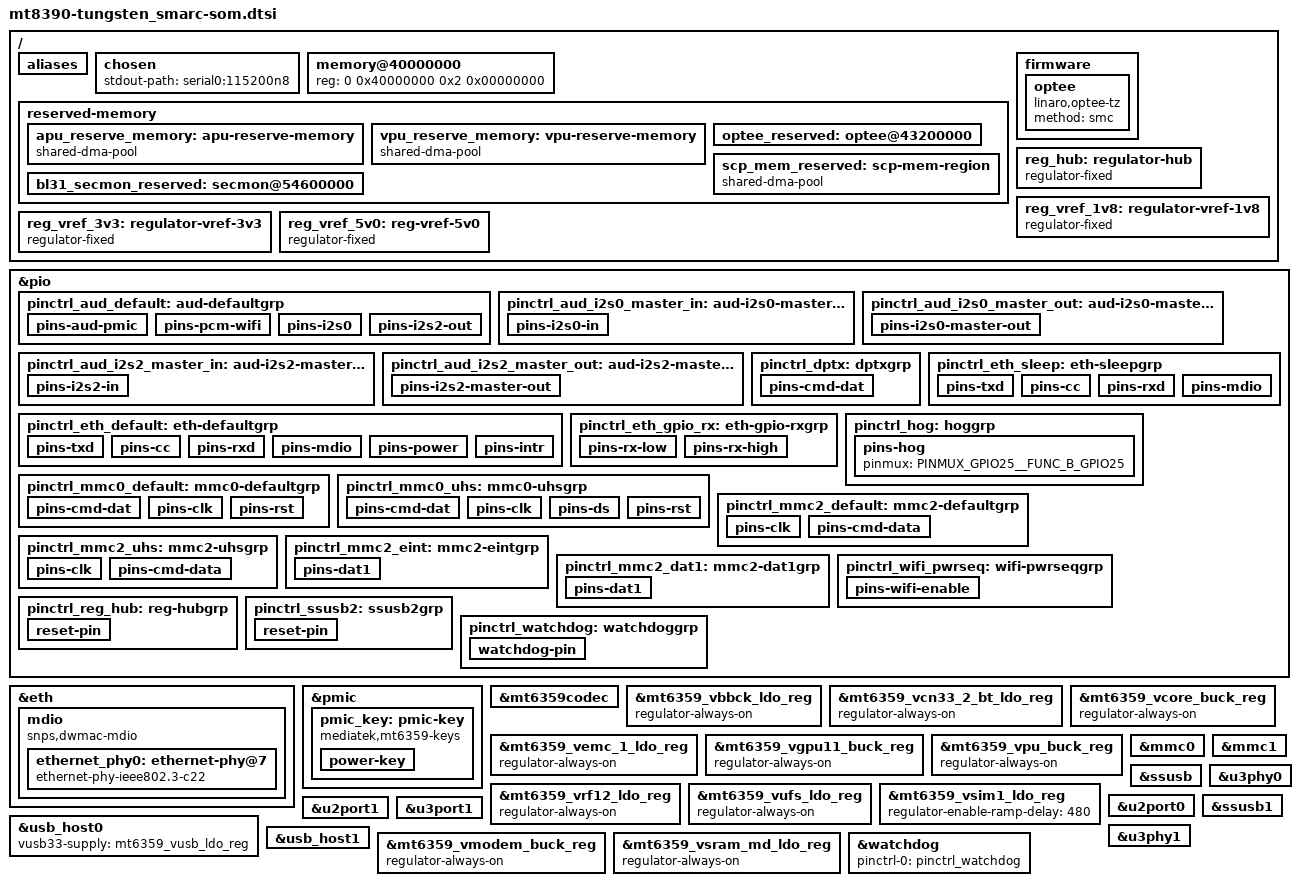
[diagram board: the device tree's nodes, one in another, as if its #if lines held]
// SPDX-License-Identifier: (GPL-2.0 OR MIT)
/*
 * Copyright 2023 Boundary Devices
 */
/dts-v1/;
#include "mt8188.dtsi"
#include "mt6359.dtsi"
#include <dt-bindings/gpio/gpio.h>
#include <dt-bindings/input/input.h>
#include <dt-bindings/interrupt-controller/irq.h>
#include <dt-bindings/net/microchip-lan78xx.h>
#include <dt-bindings/pinctrl/mediatek,mt8188-pinfunc.h>
#include <dt-bindings/usb/pd.h>
#ifdef CONFIG_DEFCONFIG
#define UBOOT
#endif
#ifdef UBOOT
#define GPIO	gpio
#else
#define GPIO	pio
#endif

#define USE_I2SIN_WITH_I2SO1

&pio {
	pinctrl_aud_default: aud-defaultgrp {
		pins-aud-pmic {
			pinmux = <
				PINMUX_GPIO101__FUNC_O_AUD_CLK_MOSI
				PINMUX_GPIO102__FUNC_O_AUD_SYNC_MOSI
				PINMUX_GPIO103__FUNC_O_AUD_DAT_MOSI0
				PINMUX_GPIO104__FUNC_O_AUD_DAT_MOSI1
				PINMUX_GPIO105__FUNC_I0_AUD_DAT_MISO0
				PINMUX_GPIO106__FUNC_I0_AUD_DAT_MISO1
			>;
		};

		pins-pcm-wifi {
			pinmux = <
				PINMUX_GPIO121__FUNC_B0_PCM_CLK		/* PCM_CLK */
				PINMUX_GPIO122__FUNC_B0_PCM_SYNC	/* PCM_SYNC */
				PINMUX_GPIO123__FUNC_O_PCM_DO		/* PCM_DO */
				PINMUX_GPIO124__FUNC_I0_PCM_DI		/* PCM_DI */
			>;
		};

		//i2s0 I2SO1 is master
		pins-i2s0 {
			pinmux = <
				PINMUX_GPIO119__FUNC_O_I2SO1_MCK	/* I2SO2_D2 */
				PINMUX_GPIO112__FUNC_O_I2SO1_WS		/* I2SIN_D2 */
				PINMUX_GPIO120__FUNC_O_I2SO1_BCK	/* I2SO2_D3 */
				PINMUX_GPIO113__FUNC_O_I2SO1_D0		/* I2SIN_D3 */

				PINMUX_GPIO107__FUNC_B_GPIO107		/* I2SIN_MCK */
				PINMUX_GPIO108__FUNC_B_GPIO108		/* I2SIN_BCK */
				PINMUX_GPIO109__FUNC_B_GPIO109		/* I2SIN_WS */
#ifdef USE_I2SIN_WITH_I2SO1
				PINMUX_GPIO110__FUNC_I0_I2SIN_D0	/* I2SIN_D0 */
#else
				PINMUX_GPIO110__FUNC_I0_SPLIN_D0	/* I2SIN_D0 */
#endif
			>;
		};

		//i2s2
		pins-i2s2-out {
			pinmux = <
				PINMUX_GPIO116__FUNC_B0_I2SO2_WS	/* I2SO2_WS */
				PINMUX_GPIO115__FUNC_B0_I2SO2_BCK	/* I2SO2_BCK */
				PINMUX_GPIO117__FUNC_O_I2SO2_D0		/* I2SO2_D0 */
			>;
		};
	};

	pinctrl_aud_i2s0_master_in: aud-i2s0-master-ingrp {
		pins-i2s0-in {
			pinmux = <
				PINMUX_GPIO107__FUNC_I0_SPLIN_MCK	/* I2SIN_MCK */
				PINMUX_GPIO119__FUNC_B_GPIO119		/* I2SO2_D2 */
				PINMUX_GPIO108__FUNC_I0_SPLIN_LRCK	/* I2SIN_BCK */
				PINMUX_GPIO112__FUNC_B_GPIO112		/* I2SIN_D2 */
				PINMUX_GPIO109__FUNC_I0_SPLIN_BCK	/* I2SIN_WS */
				PINMUX_GPIO120__FUNC_B_GPIO120		/* I2SO2_D3 */
				PINMUX_GPIO110__FUNC_I0_SPLIN_D0	/* I2SIN_D0 */
			>;
		};
	};

	pinctrl_aud_i2s0_master_out: aud-i2s0-master-outgrp {
		pins-i2s0-master-out {
			pinmux = <
				PINMUX_GPIO107__FUNC_B_GPIO107		/* I2SIN_MCK */
				PINMUX_GPIO119__FUNC_O_I2SO1_MCK	/* I2SO2_D2 */
				PINMUX_GPIO108__FUNC_B_GPIO108		/* I2SIN_BCK */
				PINMUX_GPIO112__FUNC_O_I2SO1_WS		/* I2SIN_D2 */
				PINMUX_GPIO109__FUNC_B_GPIO109		/* I2SIN_WS */
				PINMUX_GPIO120__FUNC_O_I2SO1_BCK	/* I2SO2_D3 */
				PINMUX_GPIO113__FUNC_O_I2SO1_D0		/* I2SIN_D3 */
			>;
		};
	};

	pinctrl_aud_i2s2_master_in: aud-i2s2-master-ingrp {
		pins-i2s2-in {
			pinmux = <
				PINMUX_GPIO116__FUNC_B0_I2SIN_WS	/* I2SO2_WS */
				PINMUX_GPIO115__FUNC_B0_I2SIN_BCK	/* I2SO2_BCK */
				PINMUX_GPIO118__FUNC_I0_I2SIN_D1	/* I2SO2_D1 */
			>;
		};
	};

	pinctrl_aud_i2s2_master_out: aud-i2s2-master-outgrp {
		pins-i2s2-master-out {
			pinmux = <
				PINMUX_GPIO116__FUNC_B0_I2SO2_WS	/* I2SO2_WS */
				PINMUX_GPIO115__FUNC_B0_I2SO2_BCK	/* I2SO2_BCK */
				PINMUX_GPIO117__FUNC_O_I2SO2_D0		/* I2SO2_D0 */
			>;
		};
	};

	pinctrl_dptx: dptxgrp {
		pins-cmd-dat {
			pinmux = <PINMUX_GPIO46__FUNC_I0_DP_TX_HPD>;
			bias-pull-up;
		};
	};

	pinctrl_eth_default: eth-defaultgrp {
		pins-txd {
			pinmux = <PINMUX_GPIO131__FUNC_O_GBE_TXD3>,
				 <PINMUX_GPIO132__FUNC_O_GBE_TXD2>,
				 <PINMUX_GPIO133__FUNC_O_GBE_TXD1>,
				 <PINMUX_GPIO134__FUNC_O_GBE_TXD0>;
			drive-strength = <MTK_DRIVE_8mA>;
		};
		pins-cc {
			pinmux = <PINMUX_GPIO139__FUNC_B0_GBE_TXC>,
				 <PINMUX_GPIO142__FUNC_O_GBE_TXEN>,
				 <PINMUX_GPIO141__FUNC_I0_GBE_RXDV>,
				 <PINMUX_GPIO140__FUNC_I0_GBE_RXC>;
			drive-strength = <MTK_DRIVE_8mA>;
		};
		pins-rxd {
			pinmux = <PINMUX_GPIO135__FUNC_I0_GBE_RXD3>,
				 <PINMUX_GPIO136__FUNC_I0_GBE_RXD2>,
				 <PINMUX_GPIO137__FUNC_I0_GBE_RXD1>,
				 <PINMUX_GPIO138__FUNC_I0_GBE_RXD0>;
			drive-strength = <MTK_DRIVE_8mA>;
		};
		pins-mdio {
			pinmux = <PINMUX_GPIO143__FUNC_O_GBE_MDC>,
				 <PINMUX_GPIO144__FUNC_B1_GBE_MDIO>;
			drive-strength = <MTK_DRIVE_2mA>;
			input-enable;
		};
#ifdef UBOOT
		pins-power {
#define GP_EQOS_RESET	<&GPIO 27 GPIO_ACTIVE_LOW>
			pinmux = <PINMUX_GPIO27__FUNC_B_GPIO27>;
			output-high;
		};
#endif
		pins-intr {
#define GPIRQ_EQOS_PHY	<&pio 148 IRQ_TYPE_LEVEL_LOW>
			pinmux = <PINMUX_GPIO148__FUNC_B_GPIO148>;
			input-enable;
		};
	};

	pinctrl_eth_sleep: eth-sleepgrp {
		pins-txd {
			pinmux = <PINMUX_GPIO131__FUNC_B_GPIO131>,
				 <PINMUX_GPIO132__FUNC_B_GPIO132>,
				 <PINMUX_GPIO133__FUNC_B_GPIO133>,
				 <PINMUX_GPIO134__FUNC_B_GPIO134>;
		};
		pins-cc {
			pinmux = <PINMUX_GPIO139__FUNC_B_GPIO139>,
				 <PINMUX_GPIO142__FUNC_B_GPIO142>,
				 <PINMUX_GPIO141__FUNC_B_GPIO141>,
				 <PINMUX_GPIO140__FUNC_B_GPIO140>;
		};
		pins-rxd {
			pinmux = <PINMUX_GPIO135__FUNC_B_GPIO135>,
				 <PINMUX_GPIO136__FUNC_B_GPIO136>,
				 <PINMUX_GPIO137__FUNC_B_GPIO137>,
				 <PINMUX_GPIO138__FUNC_B_GPIO138>;
		};
		pins-mdio {
			pinmux = <PINMUX_GPIO143__FUNC_B_GPIO143>,
				 <PINMUX_GPIO144__FUNC_B_GPIO144>;
			input-disable;
			bias-disable;
		};
	};

	pinctrl_eth_gpio_rx: eth-gpio-rxgrp {
		pins-rx-low {
			pinmux =
#define GP_PHY_RX_CTL		<&GPIO 141 GPIO_ACTIVE_HIGH>
				<PINMUX_GPIO141__FUNC_B_GPIO141>;
			output-low;
		};
		pins-rx-high {
			pinmux =
#define GP_PHY_RD0		<&GPIO 135 GPIO_ACTIVE_HIGH>
				<PINMUX_GPIO135__FUNC_B_GPIO135>,
#define GP_PHY_RD1		<&GPIO 136 GPIO_ACTIVE_HIGH>
				<PINMUX_GPIO136__FUNC_B_GPIO136>,
#define GP_PHY_RD2		<&GPIO 137 GPIO_ACTIVE_HIGH>
				<PINMUX_GPIO137__FUNC_B_GPIO137>,
#define GP_PHY_RD3		<&GPIO 138 GPIO_ACTIVE_HIGH>
				<PINMUX_GPIO138__FUNC_B_GPIO138>,
#define GP_PHY_RXC		<&GPIO 140 GPIO_ACTIVE_HIGH>
				<PINMUX_GPIO140__FUNC_B_GPIO140>;
			output-high;
		};
	};


	pinctrl_hog: hoggrp {
		pins-hog {
#define GP_DP0_HPD(a)	<&GPIO 25 a>	/* LCM_RST */
			pinmux = <PINMUX_GPIO25__FUNC_B_GPIO25>;
		};
	};

	pinctrl_mmc0_default: mmc0-defaultgrp {
		pins-cmd-dat {
			pinmux = <PINMUX_GPIO161__FUNC_B1_MSDC0_DAT0>,
				 <PINMUX_GPIO160__FUNC_B1_MSDC0_DAT1>,
				 <PINMUX_GPIO159__FUNC_B1_MSDC0_DAT2>,
				 <PINMUX_GPIO158__FUNC_B1_MSDC0_DAT3>,
				 <PINMUX_GPIO154__FUNC_B1_MSDC0_DAT4>,
				 <PINMUX_GPIO153__FUNC_B1_MSDC0_DAT5>,
				 <PINMUX_GPIO152__FUNC_B1_MSDC0_DAT6>,
				 <PINMUX_GPIO151__FUNC_B1_MSDC0_DAT7>,
				 <PINMUX_GPIO156__FUNC_B1_MSDC0_CMD>;
			input-enable;
			drive-strength = <MTK_DRIVE_6mA>;
			bias-pull-up = <MTK_PUPD_SET_R1R0_01>;
		};

		pins-clk {
			pinmux = <PINMUX_GPIO157__FUNC_B1_MSDC0_CLK>;
			drive-strength = <MTK_DRIVE_6mA>;
			bias-pull-down = <MTK_PUPD_SET_R1R0_10>;
		};

		pins-rst {
			pinmux = <PINMUX_GPIO155__FUNC_O_MSDC0_RSTB>;
			drive-strength = <MTK_DRIVE_6mA>;
			bias-pull-up = <MTK_PUPD_SET_R1R0_01>;
		};
	};

	pinctrl_mmc0_uhs: mmc0-uhsgrp{
		pins-cmd-dat {
			pinmux = <PINMUX_GPIO161__FUNC_B1_MSDC0_DAT0>,
				 <PINMUX_GPIO160__FUNC_B1_MSDC0_DAT1>,
				 <PINMUX_GPIO159__FUNC_B1_MSDC0_DAT2>,
				 <PINMUX_GPIO158__FUNC_B1_MSDC0_DAT3>,
				 <PINMUX_GPIO154__FUNC_B1_MSDC0_DAT4>,
				 <PINMUX_GPIO153__FUNC_B1_MSDC0_DAT5>,
				 <PINMUX_GPIO152__FUNC_B1_MSDC0_DAT6>,
				 <PINMUX_GPIO151__FUNC_B1_MSDC0_DAT7>,
				 <PINMUX_GPIO156__FUNC_B1_MSDC0_CMD>;
			input-enable;
			drive-strength = <MTK_DRIVE_8mA>;
			bias-pull-up = <MTK_PUPD_SET_R1R0_01>;
		};

		pins-clk {
			pinmux = <PINMUX_GPIO157__FUNC_B1_MSDC0_CLK>;
			drive-strength = <MTK_DRIVE_8mA>;
			bias-pull-down = <MTK_PUPD_SET_R1R0_10>;
		};

		pins-ds {
			pinmux = <PINMUX_GPIO162__FUNC_B0_MSDC0_DSL>;
			drive-strength = <MTK_DRIVE_8mA>;
			bias-pull-down = <MTK_PUPD_SET_R1R0_10>;
		};

		pins-rst {
			pinmux = <PINMUX_GPIO155__FUNC_O_MSDC0_RSTB>;
			drive-strength = <MTK_DRIVE_8mA>;
			bias-pull-up = <MTK_PUPD_SET_R1R0_01>;
		};
	};

	pinctrl_mmc2_default: mmc2-defaultgrp {
		pins-clk {
			pinmux = <PINMUX_GPIO170__FUNC_B1_MSDC2_CLK>;
			drive-strength = <MTK_DRIVE_4mA>;
			bias-pull-down = <MTK_PUPD_SET_R1R0_10>;
		};

		pins-cmd-data {
			pinmux = <PINMUX_GPIO169__FUNC_B1_MSDC2_CMD>,
				 <PINMUX_GPIO171__FUNC_B1_MSDC2_DAT0>,
				 <PINMUX_GPIO172__FUNC_B1_MSDC2_DAT1>,
				 <PINMUX_GPIO173__FUNC_B1_MSDC2_DAT2>,
				 <PINMUX_GPIO174__FUNC_B1_MSDC2_DAT3>;
			input-enable;
			drive-strength = <MTK_DRIVE_6mA>;
			bias-pull-up = <MTK_PUPD_SET_R1R0_01>;
		};
	};

	pinctrl_mmc2_uhs: mmc2-uhsgrp {
		pins-clk {
			pinmux = <PINMUX_GPIO170__FUNC_B1_MSDC2_CLK>;
			drive-strength = <MTK_DRIVE_4mA>;
			bias-pull-down = <MTK_PUPD_SET_R1R0_10>;
		};

		pins-cmd-data {
			pinmux = <PINMUX_GPIO169__FUNC_B1_MSDC2_CMD>,
				 <PINMUX_GPIO171__FUNC_B1_MSDC2_DAT0>,
				 <PINMUX_GPIO172__FUNC_B1_MSDC2_DAT1>,
				 <PINMUX_GPIO173__FUNC_B1_MSDC2_DAT2>,
				 <PINMUX_GPIO174__FUNC_B1_MSDC2_DAT3>;
			input-enable;
			drive-strength = <MTK_DRIVE_6mA>;
			bias-pull-up = <MTK_PUPD_SET_R1R0_01>;
		};
	};

	pinctrl_mmc2_eint: mmc2-eintgrp {
		pins-dat1 {
#define GP_MMC2_DATA1	<&GPIO 172 GPIO_ACTIVE_HIGH>
			pinmux = <PINMUX_GPIO172__FUNC_B_GPIO172>;
			input-enable;
			bias-pull-up = <MTK_PUPD_SET_R1R0_01>;
		};
	};

	pinctrl_mmc2_dat1: mmc2-dat1grp {
		pins-dat1 {
			pinmux = <PINMUX_GPIO172__FUNC_B1_MSDC2_DAT1>;
			input-enable;
			drive-strength = <MTK_DRIVE_6mA>;
			bias-pull-up = <MTK_PUPD_SET_R1R0_01>;
		};
	};

	pinctrl_wifi_pwrseq: wifi-pwrseqgrp {
		pins-wifi-enable {
#define GP_WIFI_RESET	<&GPIO 89 GPIO_ACTIVE_LOW>
			pinmux = <PINMUX_GPIO89__FUNC_B_GPIO89>;	/* USB2_IDDIG */
			output-low;
		};
	};

	pinctrl_reg_hub: reg-hubgrp {
		reset-pin {
#define GP_HUB_ENABLE	<&GPIO 147 GPIO_ACTIVE_HIGH>			/* HUB_RESET */
			pinmux = <PINMUX_GPIO147__FUNC_B_GPIO147>;	/* DPI_HSYNC */
			output-low;
		};
	};

	pinctrl_ssusb2: ssusb2grp {
		reset-pin {
#define GP_SSUSB2_RESET	<&GPIO 80 GPIO_ACTIVE_LOW>
			pinmux = <PINMUX_GPIO80__FUNC_B_GPIO80>;	/* SPIM2_CLK */
			output-low;
		};
	};

	pinctrl_watchdog: watchdoggrp {
		watchdog-pin {
			pinmux = <PINMUX_GPIO100__FUNC_O_WATCHDOG>;	/* PMIC_WATCHDOG */
			bias-pull-up;
		};
	};
};

/ {
	aliases {
		serial0 = &uart0;
		ethernet0 = &eth;
		rtc1 = &mt6359rtc;
	};

	chosen {
		stdout-path = "serial0:115200n8";
	};

	memory@40000000 {
		device_type = "memory";
		reg = <0 0x40000000 0x2 0x00000000>;
	};

	reserved-memory {
		#address-cells = <2>;
		#size-cells = <2>;
		ranges;

		apu_reserve_memory: apu-reserve-memory{
			compatible = "shared-dma-pool";
			size = <0 0x1400000>; //20 MB
			alignment = <0 0x10000>;
			reg = <0 0x55000000 0 0x1400000>;
		};

		vpu_reserve_memory: vpu-reserve-memory {
			compatible = "shared-dma-pool";
			size = <0 0x1400000>; //20 MB
			alignment = <0 0x10000>;
			reg = <0 0x57000000 0 0x1400000>;
		};

		/* 12 MiB reserved for OP-TEE (BL32)
		 * +-----------------------+ 0x43e0_0000
		 * |      SHMEM 2MiB       |
		 * +-----------------------+ 0x43c0_0000
		 * |        | TA_RAM  8MiB |
		 * + TZDRAM +--------------+ 0x4340_0000
		 * |        | TEE_RAM 2MiB |
		 * +-----------------------+ 0x4320_0000
		 */
		optee_reserved: optee@43200000 {
			no-map;
			reg = <0 0x43200000 0 0x00c00000>;
		};

		scp_mem_reserved: scp-mem-region {
			compatible = "shared-dma-pool";
			reg = <0 0x50000000 0 0x2900000>;
			no-map;
		};

		/* 2 MiB reserved for ARM Trusted Firmware (BL31) */
		bl31_secmon_reserved: secmon@54600000 {
			no-map;
			reg = <0 0x54600000 0x0 0x200000>;
		};
	};

	firmware {
		optee {
			compatible = "linaro,optee-tz";
			method = "smc";
		};
	};

	reg_hub: regulator-hub {
		compatible = "regulator-fixed";
		enable-active-high;
		gpio = GP_HUB_ENABLE;
		pinctrl-0 = <&pinctrl_reg_hub>;
		pinctrl-names = "default";
		regulator-name = "hub_reset";
		regulator-min-microvolt = <1800000>;
		regulator-max-microvolt = <1800000>;
	};

	reg_vref_1v8: regulator-vref-1v8 {
		compatible = "regulator-fixed";
		regulator-name = "vref-1v8";
		regulator-min-microvolt = <1800000>;
		regulator-max-microvolt = <1800000>;
		regulator-always-on;
	};

	reg_vref_3v3: regulator-vref-3v3 {
		compatible = "regulator-fixed";
		regulator-name = "vref-3v3";
		regulator-min-microvolt = <3300000>;
		regulator-max-microvolt = <3300000>;
		regulator-always-on;
	};

	reg_vref_5v0: reg-vref-5v0 {
		compatible = "regulator-fixed";
		regulator-name = "vref-5v0";
		regulator-min-microvolt = <5000000>;
		regulator-max-microvolt = <5000000>;
		regulator-always-on;
	};
};

#ifndef UBOOT
&afe {
	#sound-dai-cells = <0>;
	mediatek,etdm-in1-multi-pin-mode;	/* I2S */
	mediatek,etdm-in2-multi-pin-mode;	/* I2S */
	mediatek,etdm-out1-multi-pin-mode;	/* I2S */
	mediatek,etdm-out2-multi-pin-mode;	/* I2S */
#ifdef USE_I2SIN_WITH_I2SO1
	mediatek,etdm-in1-cowork-source = <3>;	/* clocks from etdm2_out */
	mediatek,etdm-in2-cowork-source = <2>;	/* clocks from etdm1_out */
#else
	mediatek,etdm-in1-cowork-source = <2>;	/* clocks from etdm1_out */
	mediatek,etdm-in2-cowork-source = <3>;	/* clocks from etdm2_out */
#endif
	status = "okay";
};
#endif

&eth {
	avddh-supply = <&mt6359_vpa_buck_reg>;
	mediatek,mac-wol;
	phy-mode ="rgmii-rxid";
	phy-handle = <&ethernet_phy0>;
	pinctrl-names = "default", "sleep", "gpio-rx";
	pinctrl-0 = <&pinctrl_eth_default>;
	pinctrl-1 = <&pinctrl_eth_sleep>;
	pinctrl-2 = <&pinctrl_eth_gpio_rx>;
	status = "okay";

	mdio {
		compatible = "snps,dwmac-mdio";
		#address-cells = <1>;
		#size-cells = <0>;

		ethernet_phy0: ethernet-phy@7 {
			compatible = "ethernet-phy-ieee802.3-c22";
			eee-broken-1000t;
			interrupts-extended = GPIRQ_EQOS_PHY;
			reg = <0x7>;
#ifdef GP_EQOS_RESET
			reset-gpios = GP_EQOS_RESET;
#endif
		};
	};
};

#ifndef UBOOT
&dpi1 {
	status = "okay";
};

&dp_intf1 {
	status = "disabled";
	ports {
		port {
			dp_intf1_out: endpoint {
				remote-endpoint = <&dptx_in>;
			};
		};
	};
};

&dp_tx {
	pinctrl-names = "default";
	pinctrl-0 = <&pinctrl_dptx>;
	status = "disabled";

	ports {
		port {
			dptx_in: endpoint {
				remote-endpoint = <&dp_intf1_out>;
			};
		};
	};
};

&dsi0 {
	#address-cells = <1>;
	#size-cells = <0>;
	poweron-in-hs-mode = <0>;
};

&dsi1 {
	#address-cells = <1>;
	#size-cells = <0>;
	poweron-in-hs-mode = <0>;
};

&dmic_codec {
	wakeup-delay-ms = <200>;
};

&hdmi0 {
	status = "okay";
};
#endif

&pmic {
	interrupt-parent = <&pio>;
	interrupts = <222 IRQ_TYPE_LEVEL_HIGH>;

	/delete-node/ mt6359keys;

	pmic_key: pmic-key {
		compatible = "mediatek,mt6359-keys";
		mediatek,long-press-mode = <1>;
		power-off-time-sec = <0>;

		power-key{
			linux,keycodes = <KEY_POWER>;
			wakeup-source;
		};
	};
};

#ifndef UBOOT
&scp {
	memory-region = <&scp_mem_reserved>;
	status = "okay";
};
#endif

&mt6359codec {
	mediatek,mic-type-0 = <1>; /* ACC */
	mediatek,mic-type-1 = <3>; /* DCC */
	mediatek,mic-type-2 = <0>;
	mediatek,dmic-mode = <0>;
};

&mt6359_vbbck_ldo_reg {
	regulator-always-on;
};

&mt6359_vcn33_2_bt_ldo_reg {
	regulator-always-on;
};

&mt6359_vcore_buck_reg {
	regulator-always-on;
};

&mt6359_vemc_1_ldo_reg {
	regulator-always-on;
};

&mt6359_vgpu11_buck_reg {
	regulator-always-on;
};

&mt6359_vpu_buck_reg {
	regulator-always-on;
};

&mt6359_vrf12_ldo_reg {
	regulator-always-on;
};

&mt6359_vufs_ldo_reg {
	regulator-always-on;
};

&mmc0 {
	bus-width = <8>;
	cap-mmc-highspeed;
	cap-mmc-hw-reset;
	hs400-ds-delay = <0x1481b>;
	max-frequency = <200000000>;
	mmc-hs200-1_8v;
	mmc-hs400-1_8v;
	non-removable;
	no-sdio;
	no-sd;
	pinctrl-names = "default", "state_uhs";
	pinctrl-0 = <&pinctrl_mmc0_default>;
	pinctrl-1 = <&pinctrl_mmc0_uhs>;
	status = "okay";
	supports-cqe;
	vmmc-supply = <&mt6359_vemc_1_ldo_reg>;
	vqmmc-supply = <&mt6359_vufs_ldo_reg>;
};

&mmc1 {
	cap-sd-highspeed;
	max-frequency = <200000000>;
	sd-uhs-sdr50;
	sd-uhs-sdr104;
	status = "okay";
	vqmmc-supply = <&mt6359_vsim1_ldo_reg>;
};

&mt6359_vsim1_ldo_reg {
	regulator-enable-ramp-delay = <480>;
};

#ifndef UBOOT
&wifi_pwrseq {
	status = "okay";
	pinctrl-names = "default";
	pinctrl-0 = <&pinctrl_wifi_pwrseq>;
	reset-gpios = GP_WIFI_RESET;
	post-power-on-delay-ms = <200>;
};

&mmc2 {
	status = "okay";
	pinctrl-names = "default", "state_uhs", "state_eint",
					"state_dat1";
	pinctrl-0 = <&pinctrl_mmc2_default>;
	pinctrl-1 = <&pinctrl_mmc2_uhs>;
	pinctrl-2 = <&pinctrl_mmc2_eint>;
	pinctrl-3 = <&pinctrl_mmc2_dat1>;
	eint-gpios = GP_MMC2_DATA1;
	bus-width = <4>;
	max-frequency = <200000000>;
	cap-sd-highspeed;
	sd-uhs-sdr104;
	keep-power-in-suspend;
	enable-sdio-wakeup;
	cap-sdio-async-int;
	cap-sdio-irq;
	no-mmc;
	no-sd;
	non-removable;
	vmmc-supply = <&reg_vref_3v3>;
	vqmmc-supply = <&reg_vref_1v8>;
	mmc-pwrseq = <&wifi_pwrseq>;
};
#endif

#ifndef UBOOT
&spmi {
	#address-cells = <2>;
	#size-cells = <1>;

	mt6315_6: mt6315@6 {
		compatible = "mediatek,mt6315-regulator";
		reg = <0x6 0 0xb>;

		regulators {
			mt6315_6_vbuck1: vbuck1 {
				regulator-compatible = "vbuck1";
				regulator-name = "Vbcpu";
				regulator-min-microvolt = <300000>;
				regulator-max-microvolt = <1193750>;
				regulator-enable-ramp-delay = <256>;
				regulator-allowed-modes = <0 1 2>;
				regulator-always-on;
				mtk,combined-regulator = <2>;
			};
			mt6315_6_vbuck3: vbuck3 {
				regulator-compatible = "vbuck3";
				regulator-name = "Vdd2";
				regulator-min-microvolt = <300000>;
				regulator-max-microvolt = <1193750>;
				regulator-enable-ramp-delay = <256>;
				regulator-allowed-modes = <0 1 2>;
				regulator-always-on;
			};
			mt6315_6_vbuck4: vbuck4 {
				regulator-compatible = "vbuck4";
				regulator-name = "Vddq";
				regulator-min-microvolt = <300000>;
				regulator-max-microvolt = <1193750>;
				regulator-enable-ramp-delay = <256>;
				regulator-allowed-modes = <0 1 2>;
				regulator-always-on;

				regulator-state-mem {
					regulator-on-in-suspend;
					regulator-suspend-microvolt = <1193750>;
				};
			};
		};
	};
};

&pciephy {
	status = "okay";
};
#endif

&ssusb {
	maximum-speed = "high-speed";
	mediatek,force-vbus-peripheral;
	vusb33-supply = <&mt6359_vusb_ldo_reg>;
	wakeup-source;
};

#ifndef UBOOT
&spi0 {
	mediatek,pad-select = <0>;
};

&spi1 {
	mediatek,pad-select = <0>;
};
#endif

&u2port0 {
	status = "okay";
};

&u3phy0 {
	status = "okay";
};

&usb_host0 {
	status = "okay";
	vusb33-supply = <&mt6359_vusb_ldo_reg>;
};

&ssusb1 {
	dr_mode = "host";
	mediatek,force-vbus;
	status = "okay";
	vusb33-supply = <&mt6359_vusb_ldo_reg>;
	wakeup-source;
};

&u2port1 {
	status = "okay";
};

&u3port1 {
	status = "okay";
};

&u3phy1 {
	status = "okay";
};

&usb_host1 {
	status = "okay";
	vusb33-supply = <&mt6359_vusb_ldo_reg>;
	vbus-supply = <&reg_hub>;
};

#ifndef UBOOT
&ssusb2 {
	dr_mode = "host";
	maximum-speed = "high-speed";
	mediatek,force-vbus;
	pinctrl-0 = <&pinctrl_ssusb2>;
	pinctrl-names = "default";
	status = "okay";
	vusb33-supply = <&mt6359_vusb_ldo_reg>;
	wakeup-source;
};

&u2port2 {
	status = "okay";
};

&u3phy2 {
	status = "okay";
};

&usb_host2 {
	status = "okay";
	vusb33-supply = <&mt6359_vusb_ldo_reg>;
	vdd1p2-supply = <&mt6315_6_vbuck4>;
	reset-gpios = GP_SSUSB2_RESET;
	#address-cells = <1>;
	#size-cells = <0>;

	ethernet: ethernet@1 {
		compatible = "usb424,7850";
		reg = <1>;

		#address-cells = <1>;
		#size-cells = <0>;
		mdio {
			#address-cells = <0x1>;
			#size-cells = <0x0>;
			eth_phy: ethernet-phy@1 {
				reg = <1>;
				/* Lines are LEDs 0 - 3 respectivly.
				 *  We only use led 0(LINK1000) and 2(LINK_ACT)
				 */
				microchip,led-modes = <
					LAN78XX_LINK_1000_ACTIVITY
					LAN78XX_LINK_10_ACTIVITY
					LAN78XX_LINK_ACTIVITY
					LAN78XX_LINK_10_100_ACTIVITY
				>;
			};
		};
	};
};
#endif

#ifndef UBOOT
&mfg0 {
	domain-supply = <&mt6359_vproc2_buck_reg>;
};
#endif

&mt6359_vmodem_buck_reg {
	regulator-always-on;
};

&mt6359_vsram_md_ldo_reg {
	regulator-always-on;
};

#ifndef UBOOT
&sound {
	compatible = "mediatek,mt8390-evk";
	model = "mt8390-evk";
	pinctrl-names = "default";
	pinctrl-0 = <&pinctrl_aud_default>;

	audio-routing =
		"Headphone", "Headphone L",
		"Headphone", "Headphone R",
		"Headphone", "HPOUTL",
		"Headphone", "HPOUTR",
		"Headphone", "SPKOUTL",
		"Headphone", "SPKOUTR",
		"Headset Mic", "MICBIAS",
		"IN1R", "Headset Mic",
		"IN2R", "Headset Mic",
		"IN3L", "Headset Mic",
		"IN3R", "Headset Mic";
	status = "okay";

	dai-link-0 {
		sound-dai = <&afe>;
		dai-link-name = "ADDA_BE";
		status = "okay";

		codec-0 {
			sound-dai = <&pmic 0>;
		};

		codec-1 {
			sound-dai = <&dmic_codec>;
		};
	};

	dai-link-1 {
		sound-dai = <&afe>;
		dai-link-name = "ETDM3_OUT_BE";
		status = "okay";

		codec-0 {
			sound-dai = <&hdmi0>;
		};
	};

	dai-link-2 {
		sound-dai = <&afe>;
		dai-link-name = "DPTX_BE";
		status = "disabled";

		codec-0 {
			sound-dai = <&dp_tx>;
		};
	};

	dai-link-3 {
		sound-dai = <&afe>;
		dai-link-name = "ETDM1_OUT_BE";
		status = "okay";

		codec-0 {
			sound-dai = <&wm8962>;
		};
	};

	dai-link-4 {
		sound-dai = <&afe>;
#ifdef USE_I2SIN_WITH_I2SO1
		dai-link-name = "ETDM2_IN_BE";
#else
		dai-link-name = "ETDM1_IN_BE";
#endif
		status = "okay";

		codec-0 {
			sound-dai = <&wm8962>;
		};
	};
};

&cam_vcore {
	domain-supply = <&mt6359_vproc1_buck_reg>;
};

&img_vcore {
	domain-supply = <&mt6359_vproc1_buck_reg>;
};
#endif

&watchdog {
	pinctrl-names = "default";
	pinctrl-0 = <&pinctrl_watchdog>;
};

#define MEDIATEK
#define IOMUX pio

/* J2A, GND and VDD_IN_01-10 */

/* J2B */
#if 0
#define SM_I2C_CSI0			i2c3
#endif
#define GP_SM_I2C_CSI0_CK(a)		<&GPIO 61 a>
#define PD_SM_I2C_CSI0_CK(a)		PINMUX_GPIO61__FUNC_B_GPIO61
#define PD_SM_I2C_CSI0_CK_I2C(a)	PINMUX_GPIO61__FUNC_B1_SCL3
#define GP_SM_I2C_CSI0_DAT(a)		<&GPIO 62 a>
#define PD_SM_I2C_CSI0_DAT(a)		PINMUX_GPIO62__FUNC_B_GPIO62
#define PD_SM_I2C_CSI0_DAT_I2C(a)	PINMUX_GPIO62__FUNC_B1_SDA3
#define DN_SM_I2C_CSI0_DAT		bias-pull-down = <MTK_PULL_SET_RSEL_011>;
#define UP_SM_I2C_CSI0_DAT		bias-pull-up = <MTK_PULL_SET_RSEL_011>;

#if 0
#define SM_I2C_CSI1			i2c4
#endif
#define GP_SM_I2C_CSI1_CK(a)		<&GPIO 63 a>
#define PD_SM_I2C_CSI1_CK(a)		PINMUX_GPIO63__FUNC_B_GPIO63
#define PD_SM_I2C_CSI1_CK_I2C(a)	PINMUX_GPIO63__FUNC_B1_SCL4
#define GP_SM_I2C_CSI1_DAT(a)		<&GPIO 64 a>
#define PD_SM_I2C_CSI1_DAT(a)		PINMUX_GPIO64__FUNC_B_GPIO64
#define PD_SM_I2C_CSI1_DAT_I2C(a)	PINMUX_GPIO64__FUNC_B1_SDA4
#define DN_SM_I2C_CSI1_DAT		bias-pull-down = <MTK_PULL_SET_RSEL_011>;
#define UP_SM_I2C_CSI1_DAT		bias-pull-up = <MTK_PULL_SET_RSEL_011>;

#define SM_PWM_CSI1			pwm3
#define GP_SM_CSI1_MCK(a)		<&GPIO 23 a>
#define PD_SM_CSI1_MCK(a)		PINMUX_GPIO23__FUNC_B_GPIO23	/* CMMCLK1 */
#define PD_SM_CSI1_MCK_CLK(a)		PINMUX_GPIO23__FUNC_O_CMMCLK1

/* J2C */
#define GP_SM_ENET0_SDP(a)		<&GPIO 14 a>
#define PD_SM_ENET0_SDP(a)		PINMUX_GPIO14__FUNC_B_GPIO14

/* J2D */
#define SM_SDIO				mmc1
#define SM_SDIO_UHS			state_uhs
#define GP_SM_SDIO_WP(a)		<&GPIO 11 a>
#define PD_SM_SDIO_WP(a)		PINMUX_GPIO11__FUNC_B_GPIO11
#define GP_SM_SDIO_CMD(a)		<&GPIO 163 a>
#define PD_SM_SDIO_CMD(a)		PINMUX_GPIO163__FUNC_B_GPIO163
#define PD_SM_SDIO_CMD_SDIO(a)		PINMUX_GPIO163__FUNC_B1_MSDC1_CMD
#define GP_SM_SDIO_CD(a)		<&GPIO 2 a>
#define PD_SM_SDIO_CD(a)		PINMUX_GPIO2__FUNC_B_GPIO2
#define DN_SM_SDIO_CD			bias-pull-down;
#define UP_SM_SDIO_CD			bias-pull-up;

#define GP_SM_SDIO_CLK(a)		<&GPIO 164 a>
#define PD_SM_SDIO_CLK(a)		PINMUX_GPIO164__FUNC_B_GPIO164
#define PD_SM_SDIO_CLK_SDIO(a)		PINMUX_GPIO164__FUNC_B1_MSDC1_CLK
#define DN_SM_SDIO_CLK			bias-pull-down = <MTK_PUPD_SET_R1R0_10>;
#define UP_SM_SDIO_CLK			bias-pull-up = <MTK_PUPD_SET_R1R0_01>;

#define GP_SM_SDIO_PWR_EN(a)		<&GPIO 111 a>
#define PD_SM_SDIO_PWR_EN(a)		PINMUX_GPIO111__FUNC_B_GPIO111		/* I2SIN_D1 */
#define DN_SM_SDIO_PWR_EN		bias-pull-down;
#define UP_SM_SDIO_PWR_EN		bias-pull-up;

#define GP_SM_SDIO_DATA0(a)		<&GPIO 165 a>
#define PD_SM_SDIO_DATA0(a)		PINMUX_GPIO165__FUNC_B_GPIO165
#define PD_SM_SDIO_DATA0_SDIO(a)	PINMUX_GPIO165__FUNC_B1_MSDC1_DAT0
#define GP_SM_SDIO_DATA1(a)		<&GPIO 166 a>
#define PD_SM_SDIO_DATA1(a)		PINMUX_GPIO166__FUNC_B_GPIO166
#define PD_SM_SDIO_DATA1_SDIO(a)	PINMUX_GPIO166__FUNC_B1_MSDC1_DAT1
#define GP_SM_SDIO_DATA2(a)		<&GPIO 167 a>
#define PD_SM_SDIO_DATA2(a)		PINMUX_GPIO167__FUNC_B_GPIO167
#define PD_SM_SDIO_DATA2_SDIO(a)	PINMUX_GPIO167__FUNC_B1_MSDC1_DAT2
#define GP_SM_SDIO_DATA3(a)		<&GPIO 168 a>
#define PD_SM_SDIO_DATA3(a)		PINMUX_GPIO168__FUNC_B_GPIO168
#define PD_SM_SDIO_DATA3_SDIO(a)	PINMUX_GPIO168__FUNC_B1_MSDC1_DAT3
#define DN_SM_SDIO_DATA3		bias-pull-down = <MTK_PUPD_SET_R1R0_10>;
#define UP_SM_SDIO_DATA3		bias-pull-up = <MTK_PUPD_SET_R1R0_01>;

#define GP_SM_GPIO13(a)			<&GPIO 5 a>
#define PD_SM_GPIO13(a)			PINMUX_GPIO5__FUNC_B_GPIO5		/* GPIO5 */
#define DN_SM_GPIO13			bias-pull-down;
#define UP_SM_GPIO13			bias-pull-up;

/* J2E */
#define SM_USBOTG_DWC			ssusb
#define GP_SM_USB0_IDDIG(a)		<&GPIO 83 GPIO_ACTIVE_HIGH>
#define PD_SM_USB0_IDDIG(a)		PINMUX_GPIO83__FUNC_B_GPIO83		/* USB0_IDDIG */
#define DN_SM_USB0_IDDIG		bias-pull-down;
#define UP_SM_USB0_IDDIG		bias-pull-up;

#define GP_SM_USB0_EN_OC(a)		<&GPIO 85 a>
#define PD_SM_USB0_EN_OC(a)		PINMUX_GPIO84__FUNC_B_GPIO84 PINMUX_GPIO85__FUNC_B_GPIO85
#define PD_SM_USB0_EN_OC_USB(a)		PINMUX_GPIO84__FUNC_B_GPIO84 PINMUX_GPIO85__FUNC_I0_VBUSVALID /* USB0_DRV_VBUS USB0_VBUS_VALID */
#define DN_SM_USB0_EN_OC		bias-pull-down;
#define UP_SM_USB0_EN_OC		bias-pull-up;

/* J2F */
#define SM_I2C_GP			i2c0
#define GP_SM_I2C_GP_CK(a)		<&GPIO 55 a>
#define PD_SM_I2C_GP_CK(a)		PINMUX_GPIO55__FUNC_B_GPIO55
#define PD_SM_I2C_GP_CK_I2C(a)		PINMUX_GPIO55__FUNC_B1_SCL0
#define GP_SM_I2C_GP_DAT(a)		<&GPIO 56 a>
#define PD_SM_I2C_GP_DAT(a)		PINMUX_GPIO56__FUNC_B_GPIO56
#define PD_SM_I2C_GP_DAT_I2C(a)		PINMUX_GPIO56__FUNC_B1_SDA0
#define DN_SM_I2C_GP_DAT		bias-pull-down = <MTK_PULL_SET_RSEL_011>;
#define UP_SM_I2C_GP_DAT		bias-pull-up = <MTK_PULL_SET_RSEL_011>;

#define SM_I2C_LCD			i2c2
#define GP_SM_I2C_LCD_CK(a)		<&GPIO 59 a>
#define PD_SM_I2C_LCD_CK(a)		PINMUX_GPIO59__FUNC_B_GPIO59
#define PD_SM_I2C_LCD_CK_I2C(a)		PINMUX_GPIO59__FUNC_B1_SCL2
#define GP_SM_I2C_LCD_DAT(a)		<&GPIO 60 a>
#define PD_SM_I2C_LCD_DAT(a)		PINMUX_GPIO60__FUNC_B_GPIO60
#define PD_SM_I2C_LCD_DAT_I2C(a)	PINMUX_GPIO60__FUNC_B1_SDA2
#define DN_SM_I2C_LCD_DAT		bias-pull-down = <MTK_PULL_SET_RSEL_011>;
#define UP_SM_I2C_LCD_DAT		bias-pull-up = <MTK_PULL_SET_RSEL_011>;

#define SM_I2C_PM			i2c1
#define GP_SM_I2C_PM_CK(a)		<&GPIO 57 a>
#define PD_SM_I2C_PM_CK(a)		PINMUX_GPIO57__FUNC_B_GPIO57
#define PD_SM_I2C_PM_CK_I2C(a)		PINMUX_GPIO57__FUNC_B1_SCL1
#define GP_SM_I2C_PM_DAT(a)		<&GPIO 58 a>
#define PD_SM_I2C_PM_DAT(a)		PINMUX_GPIO58__FUNC_B_GPIO58
#define PD_SM_I2C_PM_DAT_I2C(a)		PINMUX_GPIO58__FUNC_B1_SDA1
#define DN_SM_I2C_PM_DAT		bias-pull-down = <MTK_PULL_SET_RSEL_011>;
#define UP_SM_I2C_PM_DAT		bias-pull-up = <MTK_PULL_SET_RSEL_011>;

#define GP_SM_SMB_ALERT(a)		<&GPIO 12 a>
#define PD_SM_SMB_ALERT(a)		PINMUX_GPIO12__FUNC_B_GPIO12		/* GPIO12 */

/* J2G */
#ifndef UBOOT
#define SM_FB_HDMI			hdmi0

#define MIPI_DSI			dsi0
#define SM_FB_MIPI			dsi0
#define SM_FB_MIPI_SUBSYSTEM		dsi0
#define SM_MIPI_PHY_CLOCK		<&vdosys0 CLK_VDO0_DSI0_DSI>

#define MIPI1_DSI			dsi1
#define SM_FB_MIPI1			dsi1
#define SM_FB_MIPI1_SUBSYSTEM		dsi1
#define SM_MIPI1_PHY_CLOCK		<&vdosys0 CLK_VDO0_DSI1_DSI>
#endif

#define MIPI_ADD_PORT
#define GP_SM_LCD0_BKLT_EN(a)		<&GPIO 146 a>
#define PD_SM_LCD0_BKLT_EN(a)		PINMUX_GPIO146__FUNC_B_GPIO146		/* DPI_D15 */
#define DN_SM_LCD0_BKLT_EN		bias-pull-down = <MTK_PUPD_SET_R1R0_10>;
#define UP_SM_LCD0_BKLT_EN		bias-pull-up = <MTK_PUPD_SET_R1R0_01>;

#define GP_SM_LCD0_VDD_EN(a)		<&GPIO 26 a>
#define PD_SM_LCD0_VDD_EN(a)		PINMUX_GPIO26__FUNC_B_GPIO26		/* DSI0_TE */
#define DN_SM_LCD0_VDD_EN		bias-pull-down;
#define UP_SM_LCD0_VDD_EN		bias-pull-up;

#define SM_PWM_LCD0			disp_pwm0
#define GP_SM_LCD0_BKLT_PWM(a)		<&GPIO 29 a>
#define PD_SM_LCD0_BKLT_PWM(a)		PINMUX_GPIO29__FUNC_B_GPIO29
#define PD_SM_LCD0_BKLT_PWM_OUT(a)	PINMUX_GPIO29__FUNC_O_DISP_PWM0		/* DISP_PWM0 */
#define DN_SM_LCD0_BKLT_PWM		bias-pull-down;
#define UP_SM_LCD0_BKLT_PWM		bias-pull-up;

#define GP_SM_EDP0_HPD(a)		<&GPIO 28 a>
#define PD_SM_EDP0_HPD(a)		PINMUX_GPIO28__FUNC_B_GPIO28
#define PD_SM_EDP0_HPD_IN(a)		PINMUX_GPIO28__FUNC_I0_EDP_TX_HPD	/* DSI1_TE */
#define DN_SM_EDP0_HPD			bias-pull-down;
#define UP_SM_EDP0_HPD			bias-pull-up;

#define GP_SM_EDP1_HPD(a)		<&GPIO 19 a>
#define PD_SM_EDP1_HPD(a)		PINMUX_GPIO19__FUNC_B_GPIO19		/* CMMRST0 */
#define DN_SM_EDP1_HPD			bias-pull-down;
#define UP_SM_EDP1_HPD			bias-pull-up;

#define GP_SM_LCD1_VDD_EN(a)		<&GPIO 46 a>
#define PD_SM_LCD1_VDD_EN(a)		PINMUX_GPIO46__FUNC_B_GPIO46		/* DPTX_HPD */
#define DN_SM_LCD1_VDD_EN		bias-pull-down;
#define UP_SM_LCD1_VDD_EN		bias-pull-up;

#define SM_PWM_LCD1			disp_pwm1
#define GP_SM_LCD1_BKLT_PWM(a)		<&GPIO 30 a>
#define PD_SM_LCD1_BKLT_PWM(a)		PINMUX_GPIO30__FUNC_B_GPIO30
#define PD_SM_LCD1_BKLT_PWM_OUT(a)	PINMUX_GPIO30__FUNC_O_DISP_PWM1		/* DISP_PWM1 */
#define DN_SM_LCD1_BKLT_PWM		bias-pull-down;
#define UP_SM_LCD1_BKLT_PWM		bias-pull-up;

#define GP_SM_LVDS1_BACKLIGHT_EN(a)	<&GPIO 15 a>
#define PD_SM_LVDS1_BACKLIGHT_EN(a)	PINMUX_GPIO15__FUNC_B_GPIO15		/* GPIO15 */
#define DN_SM_LVDS1_BACKLIGHT_EN	bias-pull-down;
#define UP_SM_LVDS1_BACKLIGHT_EN	bias-pull-up;

/* J2H */
#ifndef UBOOT
#define SM_PCIE				pcie
#endif
#define GP_SM_PCIE_A_RST(a)		<&GPIO 48 a>
#define PD_SM_PCIE_A_RST(a)		PINMUX_GPIO48__FUNC_B_GPIO48
#define PD_SM_PCIE_A_RST_OUT(a)		PINMUX_GPIO48__FUNC_O_PERSTN		/* PCIE_PERESET_N */
#define GP_SM_PCIE_WAKE(a)		<&GPIO 47 a>
#define PD_SM_PCIE_WAKE(a)		PINMUX_GPIO47__FUNC_B_GPIO47
#define PD_SM_PCIE_WAKE_IN(a)		PINMUX_GPIO47__FUNC_I1_WAKEN		/* PCIE_WAKE_N */
#define GP_SM_PCIE_CLK_REQ(a)		<&GPIO 49 a>
#define PD_SM_PCIE_CLK_REQ(a)		PINMUX_GPIO49__FUNC_B_GPIO49
#define PD_SM_PCIE_CLK_REQ_OUT(a)	PINMUX_GPIO49__FUNC_B1_CLKREQN		/* PCIE_CLKREQ_N */
#define DN_SM_PCIE_CLK_REQ		bias-pull-down;
#define UP_SM_PCIE_CLK_REQ		bias-pull-up;

/* J2I */
#define SM_AFE				afe
#define SM_AUDIO_MCK			<&topckgen CLK_TOP_I2SO1>
#define GP_SM_AUDIO_MCK(a)		<&GPIO 119 a>
#define PD_SM_AUDIO_MCK(a)		PINMUX_GPIO107__FUNC_B_GPIO107 PINMUX_GPIO119__FUNC_B_GPIO119
#define PD_SM_AUDIO_MCK_I2S(a)		PINMUX_GPIO107__FUNC_I0_SPLIN_MCK PINMUX_GPIO119__FUNC_O_I2SO1_MCK	/* I2SIN_MCK, I2SO2_D2 */

#define GP_SM_I2S0_LRCK(a)		<&GPIO 112 a>
#define PD_SM_I2S0_LRCK(a)		PINMUX_GPIO108__FUNC_B_GPIO108 PINMUX_GPIO112__FUNC_B_GPIO112
#define PD_SM_I2S0_LRCK_I2S(a)		PINMUX_GPIO108__FUNC_I0_SPLIN_LRCK PINMUX_GPIO112__FUNC_O_I2SO1_WS	/* I2SIN_BCK I2SIN_D2 */

#define GP_SM_I2S0_SDOUT(a)		<&GPIO 113 a>
#define PD_SM_I2S0_SDOUT(a)		PINMUX_GPIO113__FUNC_B_GPIO113
#define PD_SM_I2S0_SDOUT_I2S(a)		PINMUX_GPIO113__FUNC_O_I2SO1_D0		/* I2SIN_D3 */

#define GP_SM_I2S0_SDIN(a)		<&GPIO 110 a>
#define PD_SM_I2S0_SDIN(a)		PINMUX_GPIO110__FUNC_B_GPIO110
#define PD_SM_I2S0_SDIN_I2S(a)		PINMUX_GPIO110__FUNC_I0_SPLIN_D0	/* I2SIN_D0 */

#define GP_SM_I2S0_CK(a)		<&GPIO 120 a>
#define PD_SM_I2S0_CK(a)		PINMUX_GPIO109__FUNC_B_GPIO109 PINMUX_GPIO120__FUNC_B_GPIO120
#define PD_SM_I2S0_CK_I2S(a)		PINMUX_GPIO109__FUNC_I0_SPLIN_BCK PINMUX_GPIO120__FUNC_O_I2SO1_BCK	/* I2SIN_WS I2SO2_D3 */

#define GP_SM_I2S2_LRCK(a)		<&GPIO 116 a>
#define PD_SM_I2S2_LRCK(a)		PINMUX_GPIO116__FUNC_B_GPIO116
#define PD_SM_I2S2_LRCK_I2S(a)		PINMUX_GPIO116__FUNC_B0_I2SIN_WS	/* I2SO2_WS */

#define GP_SM_I2S2_SDOUT(a)		<&GPIO 117 a>
#define PD_SM_I2S2_SDOUT(a)		PINMUX_GPIO117__FUNC_B_GPIO117
#define PD_SM_I2S2_SDOUT_I2S(a)		PINMUX_GPIO117__FUNC_O_I2SO2_D0		/* I2SO2_D0 */

#define GP_SM_I2S2_SDIN(a)		<&GPIO 118 a>
#define PD_SM_I2S2_SDIN(a)		PINMUX_GPIO118__FUNC_B_GPIO118
#define PD_SM_I2S2_SDIN_I2S(a)		PINMUX_GPIO118__FUNC_I0_I2SIN_D1	/* I2SO2_D1 */

#define GP_SM_I2S2_CK(a)		<&GPIO 115 a>
#define PD_SM_I2S2_CK(a)		PINMUX_GPIO115__FUNC_B_GPIO115
#define PD_SM_I2S2_CK_I2S(a)		PINMUX_GPIO115__FUNC_B0_I2SIN_BCK	/* I2SO2_BCK */

/* J2J */
#define GP_SM_GPIO12(a)			<&pio 42 a>
#define PD_SM_GPIO12(a)			PINMUX_GPIO42__FUNC_B_GPIO42		/* KPCOL0 */
#define GP_SM_WDT_TIMEOUT(a)		<&GPIO 100 a>
#define PD_SM_WDT_TIMEOUT(a)		PINMUX_GPIO100__FUNC_B_GPIO100
#define PD_SM_WDT_TIMEOUT_WDT(a)	PINMUX_GPIO100__FUNC_O_WATCHDOG		/* PMIC_WATCHDOG */
#define GP_SM_LID(a)			<&GPIO 65 a>
#define PD_SM_LID(a)			PINMUX_GPIO65__FUNC_B_GPIO65		/* SCL5 */
#define GP_SM_SLEEP(a)			<&GPIO 66 a>
#define PD_SM_SLEEP(a)			PINMUX_GPIO66__FUNC_B_GPIO66		/* SDA5 */
#define DN_SM_SLEEP			bias-pull-down;
#define UP_SM_SLEEP			bias-pull-up;

#define GP_SM_CHARGING(a)		<&GPIO 88 a>
#define PD_SM_CHARGING(a)		PINMUX_GPIO88__FUNC_B_GPIO88		/* USB1_VBUS_VALID */
#define GP_SM_CHARGER_PRESENT(a)	<&GPIO 129 a>
#define PD_SM_CHARGER_PRESENT(a)	PINMUX_GPIO129__FUNC_B_GPIO129		/* DMIC2_DAT */
#define GP_SM_CARRIER_STANDBY(a)	<&GPIO 128 a>
#define PD_SM_CARRIER_STANDBY(a)	PINMUX_GPIO128__FUNC_B_GPIO128		/* DMIC2_CLK */
#define DN_SM_CARRIER_STANDBY		bias-pull-down;
#define UP_SM_CARRIER_STANDBY		bias-pull-up;

#define GP_SM_CARRIER_PWR_ON(a)		<&GPIO 127 a>
#define PD_SM_CARRIER_PWR_ON(a)		PINMUX_GPIO127__FUNC_B_GPIO127		/* DMIC1_DAT_R */
#define GP_SM_FORCE_RECOV(a)		<&GPIO 126 a>
#define PD_SM_FORCE_RECOV(a)		PINMUX_GPIO126__FUNC_B_GPIO126		/* DMIC1_DAT */
#define GP_SM_BAT_LOW(a)		<&GPIO 125 a>
#define PD_SM_BAT_LOW(a)		PINMUX_GPIO125__FUNC_B_GPIO125		/* DMIC1_CLK */
#define GP_SM_TEST(a)			<&GPIO 149 a>
#define PD_SM_TEST(a)			PINMUX_GPIO149__FUNC_B_GPIO149		/* DPI_DE */

#define GP_SM_GPIO0(a)			<&GPIO 0 a>
#define PD_SM_GPIO0(a)			PINMUX_GPIO0__FUNC_B_GPIO0		/* GPIO00 */
#define GP_SM_GPIO1(a)			<&GPIO 1 a>
#define PD_SM_GPIO1(a)			PINMUX_GPIO1__FUNC_B_GPIO1		/* GPIO01 */
#define GP_SM_GPIO2(a)			<&GPIO 50 a>
#define PD_SM_GPIO2(a)			PINMUX_GPIO50__FUNC_B_GPIO50		/* HDMITX_PWR5V */
#define GP_SM_GPIO3(a)			<&GPIO 3 a>
#define PD_SM_GPIO3(a)			PINMUX_GPIO3__FUNC_B_GPIO3		/* GPIO03 */
#define GP_SM_GPIO4(a)			<&GPIO 4 a>
#define PD_SM_GPIO4(a)			PINMUX_GPIO4__FUNC_B_GPIO4		/* GPIO04 */
#define GP_SM_GPIO5(a)			<&GPIO 10 a>
#define PD_SM_GPIO5(a)			PINMUX_GPIO10__FUNC_B_GPIO10		/* GPIO10 */
#define GP_SM_GPIO6(a)			<&GPIO 6 a>
#define PD_SM_GPIO6(a)			PINMUX_GPIO6__FUNC_B_GPIO6		/* GPIO06 */
#define DN_SM_GPIO6			bias-pull-down;
#define UP_SM_GPIO6			bias-pull-up;
#define GP_SM_GPIO7(a)			<&GPIO 7 a>
#define PD_SM_GPIO7(a)			PINMUX_GPIO7__FUNC_B_GPIO7		/* GPIO07 */
#define DN_SM_GPIO7			bias-pull-down;
#define UP_SM_GPIO7			bias-pull-up;

#define GP_SM_GPIO8(a)			<&GPIO 9 a>
#define PD_SM_GPIO8(a)			PINMUX_GPIO9__FUNC_B_GPIO9		/* GPIO09 */
#define DN_SM_GPIO8			bias-pull-down;
#define UP_SM_GPIO8			bias-pull-up;

#define GP_SM_GPIO9(a)			<&GPIO 43 a>
#define PD_SM_GPIO9(a)			PINMUX_GPIO43__FUNC_B_GPIO43		/* KPCOL1 */
#define GP_SM_GPIO10(a)			<&GPIO 44 a>
#define PD_SM_GPIO10(a)			PINMUX_GPIO44__FUNC_B_GPIO44		/* KPROW0 */
#define GP_SM_GPIO11(a)			<&pio 45 a>
#define PD_SM_GPIO11(a)			PINMUX_GPIO45__FUNC_B_GPIO45		/* KPROW1 */
#define DN_SM_GPIO11			bias-pull-down = <MTK_PUPD_SET_R1R0_10>;
#define UP_SM_GPIO11			bias-pull-up = <MTK_PUPD_SET_R1R0_01>;

#define GP_SM_RESET_OUT(a)		<&GPIO 130 a>
#define PD_SM_RESET_OUT(a)		PINMUX_GPIO130__FUNC_B_GPIO130		/* DMIC2_DAT_R */
#define GP_SM_POWER_BTN(a)
#define PD_SM_POWER_BTN(a)

/* J2K */
#ifndef UBOOT
#define SM_SPI0				spi1
#endif
#define GP_SM_SPI0_CS0(a)		<&GPIO 75 a>
#define PD_SM_SPI0_CS0(a)		PINMUX_GPIO75__FUNC_B_GPIO75
#define PD_SM_SPI0_CS0_SPI(a)		PINMUX_GPIO75__FUNC_O_SPIM1_CSB		/* SPIM1_CSB */
#define GP_SM_SPI0_CK(a)		<&GPIO 76 a>
#define PD_SM_SPI0_CK(a)		PINMUX_GPIO76__FUNC_B_GPIO76
#define PD_SM_SPI0_CK_SPI(a)		PINMUX_GPIO76__FUNC_O_SPIM1_CLK		/* SPIM1_CLK */
#define GP_SM_SPI0_DIN(a)		<&GPIO 78 a>
#define PD_SM_SPI0_DIN(a)		PINMUX_GPIO78__FUNC_B_GPIO78
#define PD_SM_SPI0_DIN_SPI(a)		PINMUX_GPIO78__FUNC_B0_SPIM1_MISO	/* SPIM1_MISO */
#define GP_SM_SPI0_DO(a)		<&GPIO 77 a>
#define PD_SM_SPI0_DO(a)		PINMUX_GPIO77__FUNC_B_GPIO77
#define PD_SM_SPI0_DO_SPI(a)		PINMUX_GPIO77__FUNC_B0_SPIM1_MOSI	/* SPIM1_MOSI */
#define GP_SM_SPI0_CS1(a)		<&GPIO 82 a>
#define PD_SM_SPI0_CS1(a)		PINMUX_GPIO82__FUNC_B_GPIO82		/* SPIM2_MISO */

#ifndef UBOOT
#define SM_ESPI				spi0
#endif
#define GP_SM_ESPI_CS0(a)		<&GPIO 69 a>
#define PD_SM_ESPI_CS0(a)		PINMUX_GPIO69__FUNC_B_GPIO69
#define PD_SM_ESPI_CS0_ESPI(a)		PINMUX_GPIO69__FUNC_O_SPIM0_CSB		/* SPIM0_CSB */
#define GP_SM_ESPI_CS1(a)		<&GPIO 91 a>
#define PD_SM_ESPI_CS1(a)		PINMUX_GPIO91__FUNC_B_GPIO91		/* USB2_VBUS_VALID */
#define DN_SM_ESPI_CS1			bias-pull-down;
#define UP_SM_ESPI_CS1			bias-pull-up;

#define GP_SM_ESPI_CK(a)		<&GPIO 70 a>
#define PD_SM_ESPI_CK(a)		PINMUX_GPIO70__FUNC_B_GPIO70
#define PD_SM_ESPI_CK_ESPI(a)		PINMUX_GPIO70__FUNC_O_SPIM0_CLK		/* SPIM0_CLK */
#define GP_SM_ESPI_IO0(a)		<&GPIO 71 a>
#define PD_SM_ESPI_IO0(a)		PINMUX_GPIO71__FUNC_B_GPIO71
#define PD_SM_ESPI_IO0_ESPI(a)		PINMUX_GPIO71__FUNC_B0_SPIM0_MOSI	/* SPIM0_MOSI */
#define GP_SM_ESPI_IO1(a)		<&GPIO 72 a>
#define PD_SM_ESPI_IO1(a)		PINMUX_GPIO72__FUNC_B_GPIO72
#define PD_SM_ESPI_IO1_ESPI(a)		PINMUX_GPIO72__FUNC_B0_SPIM0_MISO	/* SPIM0_MISO */
#define GP_SM_ESPI_ALERT0(a)		<&GPIO 81 a>
#define PD_SM_ESPI_ALERT0(a)		PINMUX_GPIO81__FUNC_B_GPIO81		/* SPIM2_MOSI */
#define GP_SM_ESPI_ALERT1(a)		<&GPIO 79 a>
#define PD_SM_ESPI_ALERT1(a)		PINMUX_GPIO79__FUNC_B_GPIO79		/* SPIM2_CSB */

#define GP_SM_ESPI_IO2(a)		<&GPIO 73 a>
#define PD_SM_ESPI_IO2(a)		PINMUX_GPIO73__FUNC_B_GPIO73		/* SPIM0_MIO2 */
#define PD_SM_ESPI_IO2_ESPI(a)		PINMUX_GPIO73__FUNC_B0_SPIM0_MIO2	/* SPIM0_MIO2 */
#define DN_SM_ESPI_IO2			bias-pull-down;
#define UP_SM_ESPI_IO2			bias-pull-up;

#define GP_SM_ESPI_IO3(a)		<&GPIO 74 a>
#define PD_SM_ESPI_IO3(a)		PINMUX_GPIO74__FUNC_B_GPIO74		/* SPIM0_MIO3 */
#define PD_SM_ESPI_IO3_ESPI(a)		PINMUX_GPIO74__FUNC_B0_SPIM0_MIO3	/* SPIM0_MIO3 */

#define GP_SM_ESPI_RESET(a)		<&GPIO 114 a>
#define PD_SM_ESPI_RESET(a)		PINMUX_GPIO114__FUNC_B_GPIO114		/* I2SO2_MCK */
#define DN_SM_ESPI_RESET		bias-pull-down;
#define UP_SM_ESPI_RESET		bias-pull-up;

/* J2L */
#define SM_SER0				uart1
#define GP_SM_SER0_TX(a)		<&GPIO 33 a>
#define PD_SM_SER0_TX(a)		PINMUX_GPIO33__FUNC_B_GPIO33
#define PD_SM_SER0_TX_UART(a)		PINMUX_GPIO33__FUNC_O_UTXD1		/* UART1_TXD */
#define DN_SM_SER0_TX			bias-pull-down;
#define UP_SM_SER0_TX			bias-pull-up;

#define GP_SM_SER0_RX(a)		<&GPIO 34 a>
#define PD_SM_SER0_RX(a)		PINMUX_GPIO34__FUNC_B_GPIO34
#define PD_SM_SER0_RX_UART(a)		PINMUX_GPIO34__FUNC_I1_URXD1		/* UART1_RXD */
#define GP_SM_SER0_RTS(a)		<&GPIO 35 a>
#define PD_SM_SER0_RTS(a)		PINMUX_GPIO35__FUNC_B_GPIO35
#define PD_SM_SER0_RTS_UART(a)		PINMUX_GPIO35__FUNC_O_URTS1		/* UART2_TXD */
#define GP_SM_SER0_CTS(a)		<&GPIO 36 a>
#define PD_SM_SER0_CTS(a)		PINMUX_GPIO36__FUNC_B_GPIO36
#define PD_SM_SER0_CTS_UART(a)		PINMUX_GPIO36__FUNC_I1_UCTS1		/* UART2_RXD */

#define SM_SER1				uart0
#define GP_SM_SER1_TX(a)		<&GPIO 31 a>
#define PD_SM_SER1_TX(a)		PINMUX_GPIO31__FUNC_B_GPIO31
#define PD_SM_SER1_TX_UART(a)		PINMUX_GPIO31__FUNC_O_UTXD0		/* UART0_TXD */
#define DN_SM_SER1_TX			bias-pull-down;
#define UP_SM_SER1_TX			bias-pull-up;

#define GP_SM_SER1_RX(a)		<&GPIO 32 a>
#define PD_SM_SER1_RX(a)		PINMUX_GPIO32__FUNC_B_GPIO32
#define PD_SM_SER1_RX_UART(a)		PINMUX_GPIO32__FUNC_I1_URXD0		/* UART0_RXD */

#define SM_SER2				uart3
#define GP_SM_SER2_TX(a)		<&GPIO 16 a>
#define PD_SM_SER2_TX(a)		PINMUX_GPIO16__FUNC_B_GPIO16
#define PD_SM_SER2_TX_UART(a)		PINMUX_GPIO16__FUNC_O_UTXD3		/* GPIO16 */
#define DN_SM_SER2_TX			bias-pull-down;
#define UP_SM_SER2_TX			bias-pull-up;

#define GP_SM_SER2_RX(a)		<&GPIO 17 a>
#define PD_SM_SER2_RX(a)		PINMUX_GPIO17__FUNC_B_GPIO17
#define PD_SM_SER2_RX_UART(a)		PINMUX_GPIO17__FUNC_I1_URXD3		/* GPIO17 */
